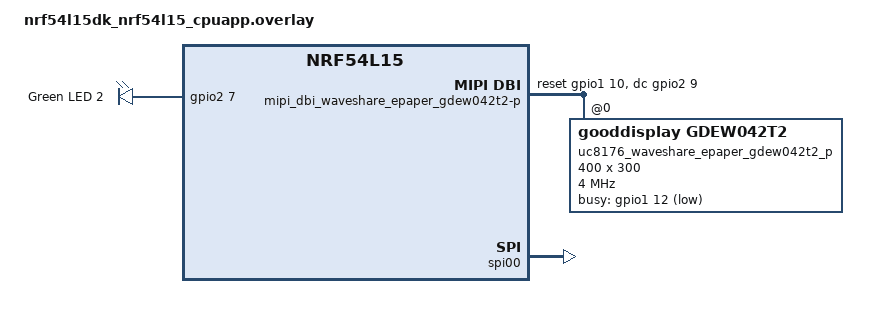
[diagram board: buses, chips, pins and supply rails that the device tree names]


/ {
	chosen {
		zephyr,display = &uc8176_waveshare_epaper_gdew042t2_p;
	};

	leds {
		compatible = "gpio-leds";
		led2: led_2 {
			gpios = <&gpio2 7 GPIO_ACTIVE_HIGH>;
			label = "Green LED 2";
		};
	};

	mipi_dbi_waveshare_epaper_gdew042t2-p {
		compatible = "zephyr,mipi-dbi-spi";
		spi-dev = <&spi00>;
		dc-gpios = <&gpio2 9 GPIO_ACTIVE_HIGH>;	/* D9 */
		reset-gpios = <&gpio1 10 GPIO_ACTIVE_HIGH>;		/* D8 */
		write-only;
		#address-cells = <1>;
		#size-cells = <0>;

		uc8176_waveshare_epaper_gdew042t2_p: uc8176@0 {
			compatible = "gooddisplay,gdew042t2", "ultrachip,uc8176";
			mipi-max-frequency = <4000000>;
			reg = <0>;
			width = <400>;
			height = <300>;
			busy-gpios = <&gpio1 12 GPIO_ACTIVE_LOW>; /* D7 */

			softstart = [ 17 17 17 ];

			full {
				cdi = <0x07>;
			};

			partial {
				pwr = [ 03 02 2b 2b ];
				cdi = <0x07>;
				pll = <0x3c>;
				vdcs = <0x08>;

				lutc = [
					00 01 0E 00 00 01
					00 00 00 00 00 00
					00 00 00 00 00 00
					00 00 00 00 00 00
					00 00 00 00 00 00
					00 00 00 00 00 00
					00 00 00 00 00 00
					00 00
				];

				lutww = [
					00 01 0E 00 00 01
					00 00 00 00 00 00
					00 00 00 00 00 00
					00 00 00 00 00 00
					00 00 00 00 00 00
					00 00 00 00 00 00
					00 00 00 00 00 00
				];

				lutkw = [
					20 01 0E 00 00 01
					00 00 00 00 00 00
					00 00 00 00 00 00
					00 00 00 00 00 00
					00 00 00 00 00 00
					00 00 00 00 00 00
					00 00 00 00 00 00
				];

				lutwk = [
					10 01 0E 00 00 01
					00 00 00 00 00 00
					00 00 00 00 00 00
					00 00 00 00 00 00
					00 00 00 00 00 00
					00 00 00 00 00 00
					00 00 00 00 00 00
				];

				lutkk = [
					00 01 0E 00 00 01
					00 00 00 00 00 00
					00 00 00 00 00 00
					00 00 00 00 00 00
					00 00 00 00 00 00
					00 00 00 00 00 00
					00 00 00 00 00 00				];
			};
		};
	};
};

&spi00 {
	status = "okay";
};

&pinctrl {
	spi00_default: spi00_default {
		group1 {
			psels = <NRF_PSEL(SPIM_SCK, 2, 7)>,
				<NRF_PSEL(SPIM_MOSI, 1, 11)>,
				<NRF_PSEL(SPIM_MISO, 1, 14)>;
		};
	};
}; 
